# pse84 register map
Vendor: Cypress Semiconductor; Series: PSE84; File version: 1.0
CPU: CM33 r0p1, little endian, MPU, FPU, VTOR, 3 interrupt priority bits
Registers are 32-bit, read-write, reset 0x0 unless marked. A register's access mark holds for its fields unless they carry their own. Offsets are from the block's base; [hi:lo] are bit positions; lines under a group give offsets from that group; {n}, {i} and the like mark numbered series.

## MS_PC5 — Master protection context value
Base 0x42295050
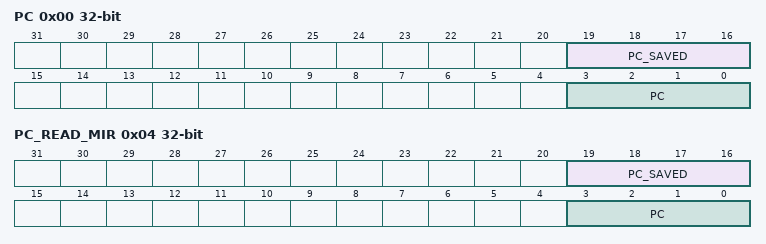
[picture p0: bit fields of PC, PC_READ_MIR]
0x00 PC — Master 'x' protection context value
  [19:16] PC_SAVED — Saved protection context. Modifications to this field are constrained by the associated MS_CTL_STRUCT[x].CTL.PC_MASK. Note: this field is ONLY used by the CM33_0.
  [3:0] PC — Active protection context (PC). Modifications to this field are constrained by the associated MS_CTL_STRUCT[x].CTL.PC_MASK value. PC[3:0] can be set to 'i' only if the corresponding mask bit (PC_MASK[i]) is '1'. The CM33_0 PC register is special: the PC field is modifiable by BOTH HW and SW (for all other masters, the PC field is modifiable by SW ONLY. For CM33_0 PC field HW modifications, the following holds: * On entry of a CM33_PC0/1/2/3_HANDLER exception/interrupt handler: IF (the new PC is the same as MS_PC_STRUCT[0].PC) PC is not affected; PC_SAVED is not affected. ELSE IF (CM33_PC_CTL.VALID[MS_PC_STRUCT[0].PC]) An AHB5 bus error is generated for the exception handler fetch; PC is not affected; PC_SAVED is not affected. ELSE PC = 'new PC'; PC_SAVED = PC (push operation). * On entry of any other exception/interrupt handler: PC = PC_SAVED; PC_SAVED is not affected (pop operation). Note that the CM33_PC0/1/2/3_HANDLER and CM33_PC_CTL registers are part of mxcm33 MMIO registers. Note: this field is NOT used by the DW controllers, DMA controllers as they inherit the protection context from master that configures the corresponding channel.
0x04 PC_READ_MIR ro — Master 'x' protection context value read mirror register
  [19:16] PC_SAVED — Read-only mirror of PC.PC_SAVED
  [3:0] PC — Read-only mirror of PC.PC

## CPUSS_SL_CTL — SYSCPUSS Internal slave control registers
Base 0x42298000
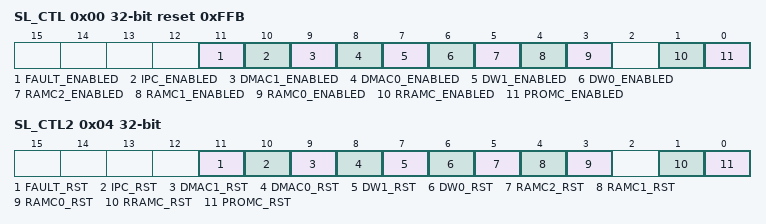
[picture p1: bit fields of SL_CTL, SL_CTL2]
0x00 SL_CTL reset 0xFFB — Slave control (Clock enables)
  [11] FAULT_ENABLED
  [10] IPC_ENABLED
  [9] DMAC1_ENABLED
  [8] DMAC0_ENABLED
  [7] DW1_ENABLED
  [6] DW0_ENABLED
  [5] RAMC2_ENABLED
  [4] RAMC1_ENABLED
  [3] RAMC0_ENABLED
  [1] RRAMC_ENABLED
  [0] PROMC_ENABLED — Slave enable controls. Each bit indicates whether the respective slave is enabled or not. 0: Disabled 1: Enabled If the slave is disabled, its clock is gated off (constant '0'). Any access (MMIO AHB access or ROM/System SRAM memory access) to slave when disabled result in AHB error response.
0x04 SL_CTL2 — Slave control2 (Reset enables)
  [11] FAULT_RST
  [10] IPC_RST
  [9] DMAC1_RST
  [8] DMAC0_RST
  [7] DW1_RST
  [6] DW0_RST
  [5] RAMC2_RST
  [4] RAMC1_RST
  [3] RAMC0_RST
  [1] RRAMC_RST
  [0] PROMC_RST — Slave reset controls. Each bit indicates whether the respective slave reset is enabled or not. 0: Disabled 1: Enabled If the slave is under reset enabled state, its clock is gated off (constant '0') and its resets are in activated state (rst_n = 0) Any access (MMIO AHB access or ROM/System SRAM memory access) to slave when disabled result in AHB error response.

## DEBUG600
Base 0x42430000
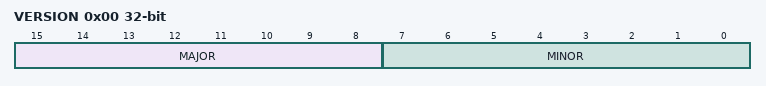
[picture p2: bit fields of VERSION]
0x00 VERSION ro reset not defined — IP Version Information
  [15:8] MAJOR — IP Major Revision Number
  [7:0] MINOR — IP Minor Revision Number

## M0SECCPUSS_STATUS — M0 Secured CPU subsystem
Base 0x42430100
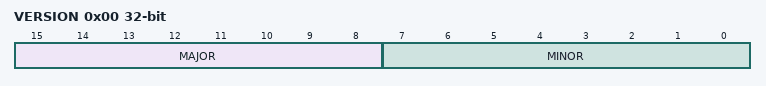
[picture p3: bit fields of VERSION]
0x00 VERSION ro reset not defined — IP Version
  [15:8] MAJOR — IP Major Revision Number Local parameter M0SEC_VERSION[15:8]
  [7:0] MINOR — IP Minor Revision Number Local parameter M0SEC_VERSION[7:0]

## HSIOM — IO Matrix (IOM)
Base 0x42800000
{0x0+0x10*i} PRT[{i}] (i=0..21) group — HSIOM port registers
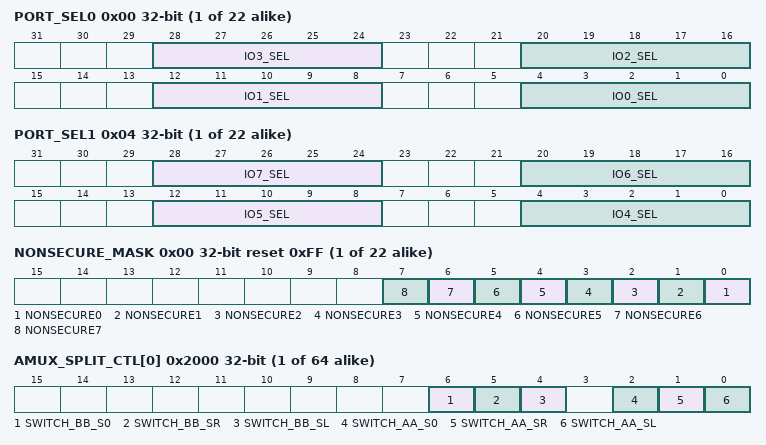
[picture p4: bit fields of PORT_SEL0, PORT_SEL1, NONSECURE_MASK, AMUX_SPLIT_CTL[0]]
  0x00 PORT_SEL0 — Port selection 0
    [28:24] IO3_SEL — Selects connection for IO pin 3 route.
    [20:16] IO2_SEL — Selects connection for IO pin 2 route.
    [12:8] IO1_SEL — Selects connection for IO pin 1 route.
    [4:0] IO0_SEL — Selects connection for IO pin 0 route.
      0=GPIO (GPIO controls 'out'); 1=GPIO_DSI (GPIO controls 'out', DSI controls 'output enable'); 2=DSI_DSI (DSI controls 'out' and 'output enable'); 3=DSI_GPIO (DSI controls 'out', GPIO controls 'output enable'); 4=AMUXA (Analog mux bus A); 5=AMUXB (Analog mux bus B); 6=AMUXA_DSI (Analog mux bus A, DSI control); 7=AMUXB_DSI (Analog mux bus B, DSI control); {v}=ACT_{v-8} (Active functionality {v-8}) (v=8..11); {v}=DS_{v-12} (DeepSleep functionality {v-12}) (v=12..15); {v}=ACT_{v-12} (Active functionality {v-12}) (v=16..27); {v}=DS_{v-24} (DeepSleep functionality {v-24}) (v=28..31)
  0x04 PORT_SEL1 — Port selection 1
    [28:24] IO7_SEL — Selects connection for IO pin 7 route.
    [20:16] IO6_SEL — Selects connection for IO pin 6 route.
    [12:8] IO5_SEL — Selects connection for IO pin 5 route.
    [4:0] IO4_SEL — Selects connection for IO pin 4 route. See PORT_SEL0 for connection details.
{0x1000+0x10*i} SECURE_PRT[{i}] (i=0..21) group — HSIOM secure attribute port registers
  0x00 NONSECURE_MASK reset 0xFF
    [n] NONSECURE{n} (n=0..7) — Non-secure attribute for IO{n}. 0 - Allows Secure access only. 1 - Allows Non-secure access only.
{0x2000+4i} AMUX_SPLIT_CTL[{i}] (i=0..63) — AMUX splitter cell control
  [6] SWITCH_BB_S0 — T-switch control for AMUXBUSB vssa/ground switch.
  [5] SWITCH_BB_SR — T-switch control for Right AMUXBUSB switch.
  [4] SWITCH_BB_SL — T-switch control for Left AMUXBUSB switch.
  [2] SWITCH_AA_S0 — T-switch control for AMUXBUSA vssa/ground switch: '0': switch open. '1': switch closed.
  [1] SWITCH_AA_SR — T-switch control for Right AMUXBUSA switch: '0': switch open. '1': switch closed.
  [0] SWITCH_AA_SL — T-switch control for Left AMUXBUSA switch: '0': switch open. '1': switch closed.
{0x2200+4i} MONITOR_CTL_{i} (i=0..3) — Power/Ground Monitor cell control {i}
  [31:0] MONITOR_EN — control for switch, which connects the power/ground supply to AMUXBUS_A/B respectively when switch is closed: '0': switch open. '1': switch closed.
